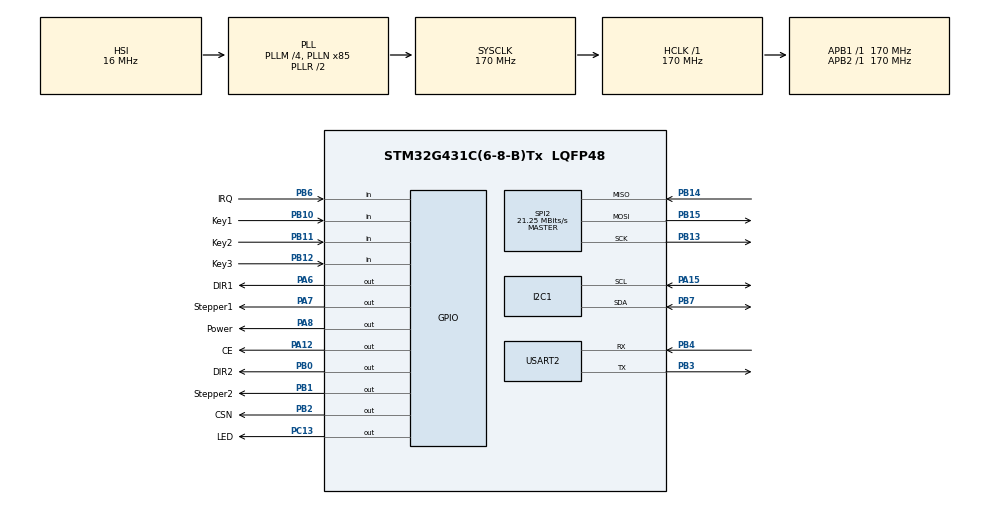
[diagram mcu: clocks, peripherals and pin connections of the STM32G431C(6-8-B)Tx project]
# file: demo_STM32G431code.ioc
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Dma.Request0=USART2_RX
Dma.Request1=USART2_TX
Dma.USART2_RX.0.Direction=DMA_PERIPH_TO_MEMORY
Dma.USART2_RX.0.EventEnable=DISABLE
Dma.USART2_RX.0.Instance=DMA1_Channel1
Dma.USART2_RX.0.MemDataAlignment=DMA_MDATAALIGN_BYTE
Dma.USART2_RX.0.MemInc=DMA_MINC_ENABLE
Dma.USART2_RX.0.Mode=DMA_NORMAL
Dma.USART2_RX.0.PeriphDataAlignment=DMA_PDATAALIGN_BYTE
Dma.USART2_RX.0.PeriphInc=DMA_PINC_DISABLE
Dma.USART2_RX.0.Polarity=HAL_DMAMUX_REQ_GEN_RISING
Dma.USART2_RX.0.Priority=DMA_PRIORITY_LOW
Dma.USART2_RX.0.RequestNumber=1
Dma.USART2_RX.0.SignalID=NONE
Dma.USART2_RX.0.SyncEnable=DISABLE
Dma.USART2_RX.0.SyncPolarity=HAL_DMAMUX_SYNC_NO_EVENT
Dma.USART2_RX.0.SyncRequestNumber=1
Dma.USART2_RX.0.SyncSignalID=NONE
Dma.USART2_TX.1.Direction=DMA_MEMORY_TO_PERIPH
Dma.USART2_TX.1.EventEnable=DISABLE
Dma.USART2_TX.1.Instance=DMA1_Channel2
Dma.USART2_TX.1.MemDataAlignment=DMA_MDATAALIGN_BYTE
Dma.USART2_TX.1.MemInc=DMA_MINC_ENABLE
Dma.USART2_TX.1.Mode=DMA_NORMAL
Dma.USART2_TX.1.PeriphDataAlignment=DMA_PDATAALIGN_BYTE
Dma.USART2_TX.1.PeriphInc=DMA_PINC_DISABLE
Dma.USART2_TX.1.Polarity=HAL_DMAMUX_REQ_GEN_RISING
Dma.USART2_TX.1.Priority=DMA_PRIORITY_LOW
Dma.USART2_TX.1.RequestNumber=1
Dma.USART2_TX.1.SignalID=NONE
Dma.USART2_TX.1.SyncEnable=DISABLE
Dma.USART2_TX.1.SyncPolarity=HAL_DMAMUX_SYNC_NO_EVENT
Dma.USART2_TX.1.SyncRequestNumber=1
Dma.USART2_TX.1.SyncSignalID=NONE
I2C1.Timing=0x40B285C2
Mcu.Family=STM32G4
Mcu.Name=STM32G431C(6-8-B)Tx
Mcu.Package=LQFP48
NVIC.DMA1_Channel1_IRQn=true\:0\:0\:false\:false\:true\:false\:true\:true
NVIC.DMA1_Channel2_IRQn=true\:0\:0\:false\:false\:true\:false\:true\:true
NVIC.PriorityGroup=NVIC_PRIORITYGROUP_4
NVIC.TIM1_UP_TIM16_IRQn=true\:0\:0\:false\:false\:true\:true\:true\:true
NVIC.TIM2_IRQn=true\:1\:0\:true\:false\:true\:true\:true\:true
NVIC.USART2_IRQn=true\:0\:0\:false\:false\:true\:true\:true\:true
PA12.GPIO_Label=CE
PA12.GPIO_PuPd=GPIO_PULLDOWN
PA12.Signal=GPIO_Output
PA13.Mode=Serial_Wire
PA13.Signal=SYS_JTMS-SWDIO
PA14.Mode=Serial_Wire
PA14.Signal=SYS_JTCK-SWCLK
PA15.Mode=I2C
PA15.Signal=I2C1_SCL
PA6.GPIO_Label=DIR1
PA6.GPIO_PuPd=GPIO_NOPULL
PA6.Signal=GPIO_Output
PA7.GPIO_Label=Stepper1
PA7.Signal=GPIO_Output
PA8.GPIO_Label=Power
PA8.Signal=GPIO_Output
PB0.GPIO_Label=DIR2
PB0.Signal=GPIO_Output
PB1.GPIO_Label=Stepper2
PB1.Signal=GPIO_Output
PB10.GPIO_Label=Key1
PB10.GPIO_PuPd=GPIO_PULLDOWN
PB10.Signal=GPIO_Input
PB11.GPIO_Label=Key2
PB11.GPIO_PuPd=GPIO_PULLDOWN
PB11.Signal=GPIO_Input
PB12.GPIO_Label=Key3
PB12.GPIO_PuPd=GPIO_PULLDOWN
PB12.Signal=GPIO_Input
PB13.Mode=Full_Duplex_Master
PB13.Signal=SPI2_SCK
PB14.Mode=Full_Duplex_Master
PB14.Signal=SPI2_MISO
PB15.Mode=Full_Duplex_Master
PB15.Signal=SPI2_MOSI
PB2.GPIO_Label=CSN
PB2.GPIO_PuPd=GPIO_PULLDOWN
PB2.Signal=GPIO_Output
PB3.Mode=Asynchronous
PB3.Signal=USART2_TX
PB4.Mode=Asynchronous
PB4.Signal=USART2_RX
PB6.GPIO_Label=IRQ
PB6.GPIO_PuPd=GPIO_PULLUP
PB6.Signal=GPIO_Input
PB7.Mode=I2C
PB7.Signal=I2C1_SDA
PC13.GPIO_Label=LED
PC13.Signal=GPIO_Output
PF0-OSC_IN.Mode=HSE-External-Oscillator
PF0-OSC_IN.Signal=RCC_OSC_IN
PF1-OSC_OUT.Mode=HSE-External-Oscillator
PF1-OSC_OUT.Signal=RCC_OSC_OUT
ProjectManager.HeapSize=0x200
ProjectManager.StackSize=0x400
ProjectManager.TargetToolchain=MDK-ARM V5.32
RCC.ADC12Freq_Value=170000000
RCC.AHBFreq_Value=170000000
RCC.APB1Freq_Value=170000000
RCC.APB1TimFreq_Value=170000000
RCC.APB2Freq_Value=170000000
RCC.APB2TimFreq_Value=170000000
RCC.CortexFreq_Value=170000000
RCC.EXTERNAL_CLOCK_VALUE=12288000
RCC.HCLKFreq_Value=170000000
RCC.HSE_VALUE=8000000
RCC.HSI48_VALUE=48000000
RCC.HSI_VALUE=16000000
RCC.LSE_VALUE=32768
RCC.PLLM=RCC_PLLM_DIV4
RCC.PLLN=85
RCC.SYSCLKFreq_VALUE=170000000
RCC.SYSCLKSource=RCC_SYSCLKSOURCE_PLLCLK
RCC.USBFreq_Value=170000000
RCC.VCOOutputFreq_Value=340000000
SPI2.BaudRatePrescaler=SPI_BAUDRATEPRESCALER_8
SPI2.CalculateBaudRate=21.25 MBits/s
SPI2.Direction=SPI_DIRECTION_2LINES
SPI2.Mode=SPI_MODE_MASTER
SPI2.VirtualType=VM_MASTER
TIM1.AutoReloadPreload=TIM_AUTORELOAD_PRELOAD_ENABLE
TIM1.PeriodNoDither=100-1
TIM1.Prescaler=17-1
TIM2.AutoReloadPreload=TIM_AUTORELOAD_PRELOAD_ENABLE
TIM2.PeriodNoDither=1000-1
TIM2.Prescaler=170-1
USART2.VirtualMode-Asynchronous=VM_ASYNC
VP_SYS_VS_DBSignals.Mode=DisableDeadBatterySignals
VP_TIM1_VS_ClockSourceINT.Mode=Internal
VP_TIM2_VS_ClockSourceINT.Mode=Internal
board=custom

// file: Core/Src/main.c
/* USER CODE BEGIN Header */
/**
  ******************************************************************************
  * @file           : main.c
  * @brief          : Main program body
  ******************************************************************************
  * @attention
  *
  * Copyright (c) 2025 STMicroelectronics.
  * All rights reserved.
  *
  * This software is licensed under terms that can be found in the LICENSE file
  * in the root directory of this software component.
  * If no LICENSE file comes with this software, it is provided AS-IS.
  *
  ******************************************************************************
  */
/* USER CODE END Header */
#include "main.h"
#include "dma.h"
#include "i2c.h"
#include "spi.h"
#include "tim.h"
#include "usart.h"
#include "gpio.h"

/* USER CODE BEGIN Includes */
#include "pca9685.h"
#include "Stepper_motor.h"
#include "Robotic_Arm.h"

extern PCA9685_HandleTypeDef hpca;
/* USER CODE END Includes */

void SystemClock_Config(void);

int main(void)
{

  /* MCU Configuration--------------------------------------------------------*/

  /* Reset of all peripherals, Initializes the Flash interface and the Systick. */
  HAL_Init();

  /* Configure the system clock */
  SystemClock_Config();

  /* Initialize all configured peripherals */
  MX_GPIO_Init();
  MX_DMA_Init();
  MX_I2C1_Init();
  MX_USART2_UART_Init();
  MX_TIM1_Init();
  MX_SPI2_Init();
  MX_TIM2_Init();
  /* USER CODE BEGIN 2 */
  HAL_TIM_Base_Start_IT(&htim1);
  HAL_TIM_Base_Start_IT(&htim2);
  Robotic_Init();

  /* USER CODE END 2 */

  /* Infinite loop */
  /* USER CODE BEGIN WHILE */
  while (1)
  {
    Robotic_KeyTest();
    // Robotic_KeyControl();
    // Robotic_UartControl_Tick();
    Robotic_UartTest();
    /* USER CODE END WHILE */

    /* USER CODE BEGIN 3 */
    // HAL_GPIO_TogglePin(GPIOC,GPIO_PIN_13);
    // HAL_Delay(180);
  }
  /* USER CODE END 3 */
}

void SystemClock_Config(void)
{
  RCC_OscInitTypeDef RCC_OscInitStruct = {0};
  RCC_ClkInitTypeDef RCC_ClkInitStruct = {0};

  /** Configure the main internal regulator output voltage
  */
  HAL_PWREx_ControlVoltageScaling(PWR_REGULATOR_VOLTAGE_SCALE1_BOOST);

  /** Initializes the RCC Oscillators according to the specified parameters
  * in the RCC_OscInitTypeDef structure.
  */
  RCC_OscInitStruct.OscillatorType = RCC_OSCILLATORTYPE_HSI;
  RCC_OscInitStruct.HSIState = RCC_HSI_ON;
  RCC_OscInitStruct.HSICalibrationValue = RCC_HSICALIBRATION_DEFAULT;
  RCC_OscInitStruct.PLL.PLLState = RCC_PLL_ON;
  RCC_OscInitStruct.PLL.PLLSource = RCC_PLLSOURCE_HSI;
  RCC_OscInitStruct.PLL.PLLM = RCC_PLLM_DIV4;
  RCC_OscInitStruct.PLL.PLLN = 85;
  RCC_OscInitStruct.PLL.PLLP = RCC_PLLP_DIV2;
  RCC_OscInitStruct.PLL.PLLQ = RCC_PLLQ_DIV2;
  RCC_OscInitStruct.PLL.PLLR = RCC_PLLR_DIV2;
  if (HAL_RCC_OscConfig(&RCC_OscInitStruct) != HAL_OK)
  {
    Error_Handler();
  }

  /** Initializes the CPU, AHB and APB buses clocks
  */
  RCC_ClkInitStruct.ClockType = RCC_CLOCKTYPE_HCLK|RCC_CLOCKTYPE_SYSCLK
                              |RCC_CLOCKTYPE_PCLK1|RCC_CLOCKTYPE_PCLK2;
  RCC_ClkInitStruct.SYSCLKSource = RCC_SYSCLKSOURCE_PLLCLK;
  RCC_ClkInitStruct.AHBCLKDivider = RCC_SYSCLK_DIV1;
  RCC_ClkInitStruct.APB1CLKDivider = RCC_HCLK_DIV1;
  RCC_ClkInitStruct.APB2CLKDivider = RCC_HCLK_DIV1;

  if (HAL_RCC_ClockConfig(&RCC_ClkInitStruct, FLASH_LATENCY_4) != HAL_OK)
  {
    Error_Handler();
  }
}

void Error_Handler(void)
{
  __disable_irq();
  while (1)
  {
  }
}
